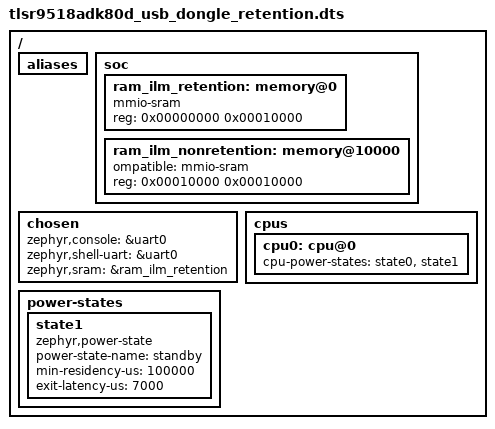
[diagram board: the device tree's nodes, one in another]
/*
 * Copyright (c) 2023 Telink Semiconductor
 *
 * SPDX-License-Identifier: Apache-2.0
 */

/dts-v1/;

#include "tlsr9518adk80d_usb_dongle-common.dtsi"

/ {
	aliases {
		/delete-property/ sw2;
		/delete-property/ sw3;
		/delete-property/ led0;
		/delete-property/ led1;
		/delete-property/ led2;
		/delete-property/ led3;
		/delete-property/ mcuboot-led0;
		/delete-property/ pwm-led0;
		/delete-property/ pwm-0;
	};

	soc {

		/delete-node/ memory@0;

		ram_ilm_retention: memory@0 {
			compatible = "mmio-sram";
		};

		ram_ilm_nonretention: memory@10000 {
			ompatible = "mmio-sram";
		};
	};
	chosen {
		zephyr,console = &uart0;
		zephyr,shell-uart = &uart0;
		zephyr,sram = &ram_ilm_retention;
	};

	cpus {
		cpu0: cpu@0 {
			cpu-power-states = <&state0 &state1>;
		};
	};

	power-states {
		state1: state1 {
			compatible = "zephyr,power-state";
			power-state-name = "standby";
			min-residency-us = <100000>;
			exit-latency-us = <7000>;
		};
	};

};

&ram_ilm_retention {
	reg = <0x00000000 0x00010000>;
};

&ram_ilm_nonretention {
	reg = <0x00010000 0x00010000>;
};
